# MSS_CCMR4 register map
Vendor: Texas Instruments
Peripheral module from a debugger description file (folder radar).
Registers are 32-bit, read-write, no defined reset value unless marked. A register's access mark holds for its fields unless they carry their own. Offsets are as the file gives them; lines under a group give offsets from that group; [hi:lo] are bit positions; {n}, {i} and the like mark numbered series; 'fields as' and 'values as' point back to an identical list; <NAME> marks a mode.

## MSS_CCMR4
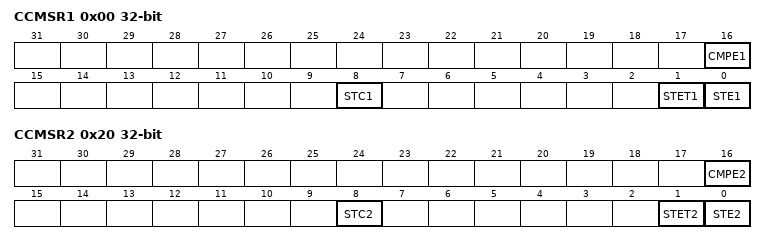
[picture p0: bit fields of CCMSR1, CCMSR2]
0x00 CCMSR1 access per field
  [16] CMPE1 rw — Compare Error 0 = CPU signals are identical 1= CPU signal compare mismatch Writes '1' to clear this bit
  [8] STC1 rw — Self Test Complete 0 = self test on-going if self test mode asserted 1 = self test is complete Writes have no effect
  [1] STET1 rw — Self Test Error Type 0 = self test failed during Compare Match test 1 = self test failed during Compare mismatch test Writes have no effect
  [0] STE1 ro — Self Test Error 0 = self test passed 1 = self test failed Writes have no effect
0x04 CCMKEYR1
  [3:0] MHEY1 — Mode Key 0000 = lock step mode 0110 = self test mode 1001 = error forcing mode 1111 = self test error forcing mode
0x20 CCMSR2
  [16] CMPE2 — Compare Error 0 = CPU signals are identical 1= CPU signal compare mismatch Writes '1' to clear this bit
  [8] STC2 — Self Test Complete 0 = self test on-going if self test mode asserted 1 = self test is complete Writes have no effect
  [1] STET2 — Self Test Error Type 0 = self test failed during Compare Match test 1 = self test failed during Compare mismatch test Writes have no effect
  [0] STE2 — Self Test Error 0 = self test passed 1 = self test failed Writes have no effect
0x24 CCMKEYR2
  [3:0] MHEY2 — Mode Key 0000 = lock step mode 0110 = self test mode 1001 = error forcing mode 1111 = self test error forcing mode
